# apollo4p register map
Vendor: Ambiq Micro; Series: Apollo; File version: 1.0
CPU: CM4 r1p0, little endian, MPU, FPU, I-cache, D-cache, VTOR, ITCM, DTCM, 3 interrupt priority bits, 0 interrupts
Registers are 32-bit, read-write, reset 0x0 unless marked. A register's access mark holds for its fields unless they carry their own. Offsets are from the block's base; [hi:lo] are bit positions; {n}, {i} and the like mark numbered series; 'fields as' and 'values as' point back to an identical list.

## APBDMA — APB DMA Register Interfaces
Base 0x40011000
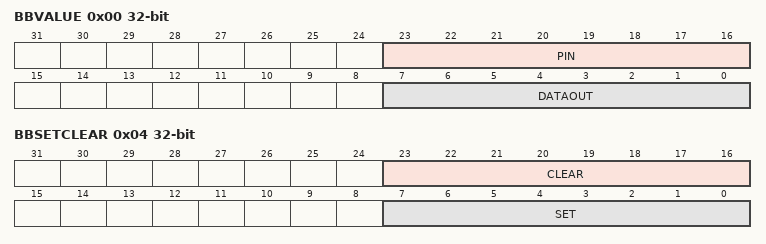
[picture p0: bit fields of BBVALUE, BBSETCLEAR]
0x00 BBVALUE — Control
  [23:16] PIN — PIO values
  [7:0] DATAOUT — Data Output Values
0x04 BBSETCLEAR — Set/Clear
  [23:16] CLEAR — Write 1 to Clear PIO value
  [7:0] SET — Write 1 to Set PIO value (set hier priority than clear if both bit set)
0x08 BBINPUT — PIO Input Values
  [7:0] DATAIN — PIO values
0x20 DEBUGDATA — PIO Input Values
0x40 DEBUG — PIO Input Values
  [3:0] DEBUGEN — Debug Enable
    0=OFF (Debug Disabled); 1=ARB (Debug Arb values)

## FPIO — Fast PIO access
Base 0x48001000
{0x0+4i} RD{i} (i=0..3) — GPIO Input {i} ({32i+31}-{32i})
  [31:0] RD{i} — GPIO{32i+31}-{32i} Reads pin state - read only. Returns the pad pin state for pins 0-31 if the PINCFG's input enable (INPEN) is active and RDZERO is inactive.
{0x10+4i} WT{i} (i=0..3) — GPIO Output {i} ({32i+31}-{32i})
  [31:0] WT{i} — GPIO{32i+31}-{32i} Reads or writes pin state. Writes of 1 bits set output pad signal if the GPIO is enabled for output. Reads return status, including sets/clears through the WTS and WTC registers.
{0x20+4i} WTS{i} (i=0..3) — GPIO Output Set {i} ({32i+31}-{32i})
  [31:0] WTS{i} — GPIO{32i+31}-{32i} Sets pin state. Writing a 1 to any bit sets the corresponding bit in the WT register if the GPIO is enabled for output. Writing a value of 0 has no effect on the corresponding bit in the WT register. Status reads should be made via the WT Register.
{0x30+4i} WTC{i} (i=0..3) — GPIO Output Clear {i} ({32i+31}-{32i})
  [31:0] WTC{i} — GPIO{32i+31}-{32i} Clears pin state. Writing a 1 to any bit clears the corresponding bit in the WT register if the GPIO is enabled for output. Writing a value of 0 has no effect on the corresponding bit in the WT register. Status reads should be made via the WT register.
{0x40+4i} EN{i} (i=0..3) — GPIO Enable {i} ({32i+31}-{32i})
  [31:0] EN{i} — GPIO{32i+31}-{32i} Enables tri-state pin output. Writing a 1 to any bit enables, and writing a 0 to any bit disables, the output for the corresponding GPIO. Reads return output enable/disable status of GPIO.
{0x50+4i} ENS{i} (i=0..3) — GPIO Enable Set {i} ({32i+31}-{32i})
  [31:0] ENS{i} — GPIO{32i+31}-{32i} Sets pin tri-state output enables. Writing a 1 to any bit sets the corresponding bit in the EN register. Writing a value of 0 has no effect on the corresponding bit in the EN register. Status reads should be made to the EN Register.
{0x60+4i} ENC{i} (i=0..3) — GPIO Enable Clear {i} ({32i+31}-{32i})
  [31:0] ENC{i} — GPIO{32i+31}-{32i} Clears pin tri-state output enables. Writing a 1 to any bit clears the corresponding bit in the EN register. Writing a value of 0 has no effect on the corresponding bit in the EN register. Status reads should be made to the EN Register.

## SECURITY — Security Interfaces
Base 0x40030000
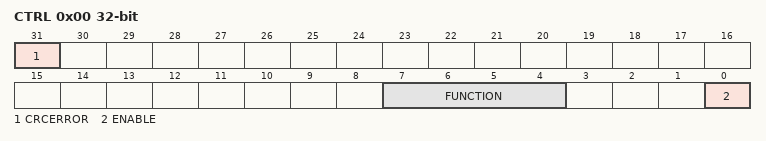
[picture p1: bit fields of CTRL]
0x00 CTRL — Control
  [31] CRCERROR — CRC Error Status - Set to 1 if an error occurs during a CRC operation. Cleared when CTRL register is written (with any value). Usually indicates an invalid address range.
  [7:4] FUNCTION — Function Select
    0=CRC32 (Perform CRC32 operation); 1=RAND (DMA pseudo-random number stream based on CRC value); 2=GENADDR (Generate DMA stream based on address)
  [0] ENABLE — Function Enable. Software should set the ENABLE bit to initiate a CRC operation. Hardware will clear the ENABLE bit upon completion.
0x10 SRCADDR — Source Addresss
  [31:0] ADDR — Source Buffer Address. Address may be byte aligned, but the length must be a multiple of 4 bits.
0x20 LEN — Length
  [23:2] LEN — Buffer size (bottom two bits assumed to be zero to ensure a multiple of 4 bytes)
0x30 RESULT — CRC Seed/Result
  [31:0] CRC — CRC Seed/Result. Software must seed the CRC with 0xFFFFFFFF before starting a CRC operation (unless the CRC is continued from a previous operation).
0x78 LOCKCTRL — LOCK Control
  [7:0] SELECT — LOCK Function Select register.
    1=LOCK01 (Enable customer OTP program.); 2=LOCK02 (Enable customer OTP read.); 17=LOCK11 (Enable Ambiq OTP program.); 18=LOCK12 (Enable Ambiq OTP read.); 157=LOCK9D (Enable Bootloader Recovery.); 158=LOCK9E (Enable Bootloader info1.); 0=RESET (Reset all.)
0x7C LOCKSTAT — LOCK Status
  [31:0] STATUS — Lock status. Bit is high to signify it is enabled. 0: LOCK01, 1: LOCK02, 4: LOCK11, 5: LOCK12, 30: LOCK9D, 31: LOCK9E
    1=LOCK01 (Enabled customer OTP program.); 2=LOCK02 (Enabled customer OTP read.); 16=LOCK11 (Enabled Ambiq OTP program.); 32=LOCK12 (Enabled Ambiq OTP read.); 0x40000000=LOCK9D (Enabled Bootloader Recovery.); 0x80000000=LOCK9E (Enabled Bootloader info1.); 0=RESET (All Reset.)
{0x80+4i} KEY{i} (i=0..3)
  [31:0] KEY{i} — Bits [{32i+31}:{32i}] of the 128-bit key should be written to this register. To protect key values, the register always returns 0x00000000.

## VCOMP — Voltage Comparator
Base 0x4000C000
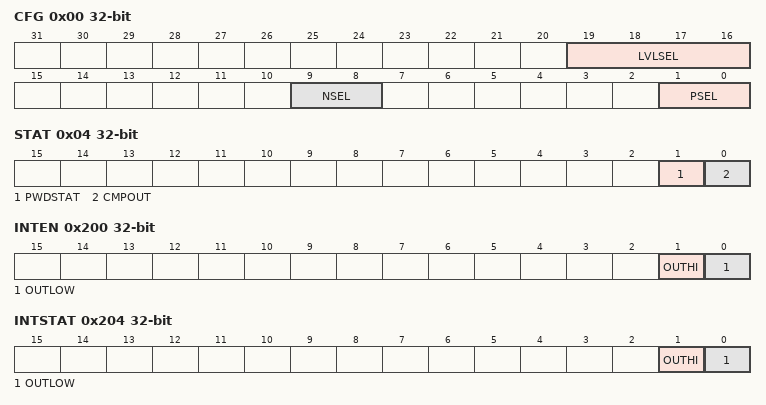
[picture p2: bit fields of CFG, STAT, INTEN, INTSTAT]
0x00 CFG — The Voltage Comparator Configuration Register contains the software control for selecting beween the 4 options for the positive input as well as the multiple options for the reference input.
  [19:16] LVLSEL — When the reference input NSEL is set to NSEL_DAC, this bitfield selects the voltage level for the negative input to the comparator.
    0=0P58V (Set Reference input to 0.58 Volts.); 1=0P77V (Set Reference input to 0.77 Volts.); 2=0P97V (Set Reference input to 0.97 Volts.); 3=1P16V (Set Reference input to 1.16 Volts.); 4=1P35V (Set Reference input to 1.35 Volts.); 5=1P55V (Set Reference input to 1.55 Volts.); 6=1P74V (Set Reference input to 1.74 Volts.); 7=1P93V (Set Reference input to 1.93 Volts.); 8=2P13V (Set Reference input to 2.13 Volts.)
  [9:8] NSEL — This bitfield selects the negative input to the comparator.
    0=VREFEXT1 (Use external reference 1 for reference input.); 1=VREFEXT2 (Use external reference 2 for reference input.); 2=VREFEXT3 (Use external reference 3 for reference input.); 3=DAC (Use DAC output selected by LVLSEL for reference input.)
  [1:0] PSEL — This bitfield selects the positive input to the comparator.
    0=VDDADJ (Use VDDADJ for the positive input.); 1=VTEMP (Use the temperature sensor output for the positive input. Note: If this channel is selected for PSEL, the bandap circuit required for temperature comparisons will automatically turn on. The bandgap circuit requires 11us to stabalize.); 2=VEXT1 (Use external voltage 0 for positive input.); 3=VEXT2 (Use external voltage 1 for positive input.)
0x04 STAT — Status
  [1] PWDSTAT — This bit indicates the power down state of the voltage comparator.
    1=POWERED_DOWN (The voltage comparator is powered down.); 0=POWERED_UP (The voltage comparator is powered up.)
  [0] CMPOUT — This bit is 1 if the positive input of the comparator is greater than the negative input.
    0=VOUT_LOW (The negative input of the comparator is greater than the positive input.); 1=VOUT_HIGH (The positive input of the comparator is greater than the negative input.)
0x08 PWDKEY — Write a value of 0x37 to unlock, write any other value to lock. This register also indicates lock status when read. When in the unlccked state (i.e. 0x37 has been written), it reads as 1. When in the locked state, it reads as 0.
  [31:0] PWDKEY — Key register value.
    55=Key (Key value to unlock the register.)
0x200 INTEN — Set bits in this register to allow this module to generate the corresponding interrupt.
  [1] OUTHI — This bit is the vcompout high interrupt.
  [0] OUTLOW — This bit is the vcompout low interrupt.
0x204 INTSTAT — Read bits from this register to discover the cause of a recent interrupt.
  fields as INTEN
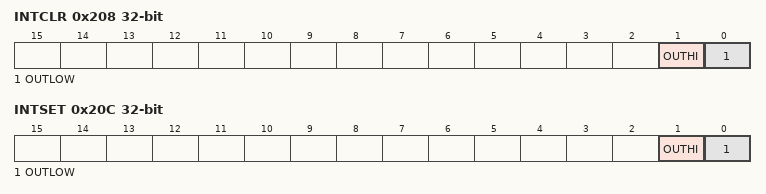
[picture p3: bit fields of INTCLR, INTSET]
0x208 INTCLR — Write a 1 to a bit in this register to clear the interrupt status associated with that bit.
  fields as INTEN
0x20C INTSET — Write a 1 to a bit in this register to instantly generate an interrupt from this module. (Generally used for testing purposes).
  fields as INTEN
